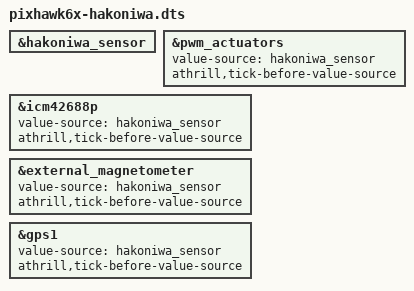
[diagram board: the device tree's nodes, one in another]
/* SPDX-License-Identifier: MIT */

#include "pixhawk6x.dts"

&hakoniwa_sensor { status = "okay"; };
&pwm_actuators {
	value-source = <&hakoniwa_sensor>;
	athrill,tick-before-value-source;
};
&icm42688p {
	value-source = <&hakoniwa_sensor>;
	athrill,tick-before-value-source;
};
&external_magnetometer {
	value-source = <&hakoniwa_sensor>;
	athrill,tick-before-value-source;
};
&gps1 {
	value-source = <&hakoniwa_sensor>;
	athrill,tick-before-value-source;
};
